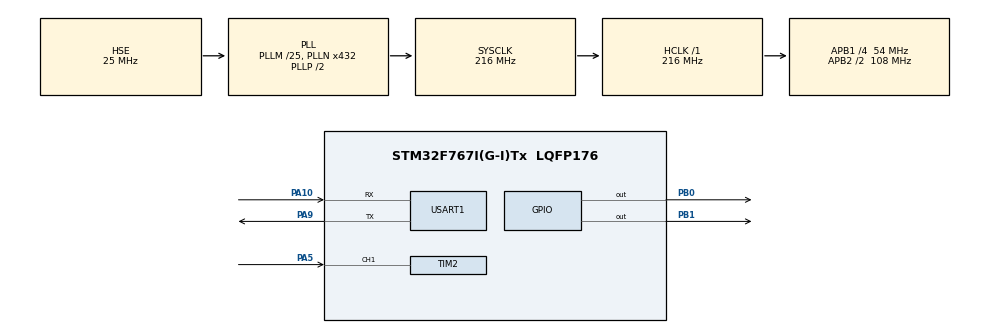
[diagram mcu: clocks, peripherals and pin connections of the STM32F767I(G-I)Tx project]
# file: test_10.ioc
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CORTEX_M7.default_mode_Activation=1
Mcu.Family=STM32F7
Mcu.Name=STM32F767I(G-I)Tx
Mcu.Package=LQFP176
NVIC.PriorityGroup=NVIC_PRIORITYGROUP_2
NVIC.USART1_IRQn=true\:3\:3\:true\:false\:true\:true\:true\:true
PA10.Mode=Asynchronous
PA10.Signal=USART1_RX
PA5.GPIO_ModeDefaultPP=GPIO_MODE_AF_PP
PA5.GPIO_PuPd=GPIO_NOPULL
PA5.GPIO_Speed=GPIO_SPEED_FREQ_HIGH
PA5.Signal=S_TIM2_CH1_ETR
PA9.Mode=Asynchronous
PA9.Signal=USART1_TX
PB0.GPIO_ModeDefaultOutputPP=GPIO_MODE_OUTPUT_PP
PB0.GPIO_PuPd=GPIO_PULLUP
PB0.GPIO_Speed=GPIO_SPEED_FREQ_HIGH
PB0.PinState=GPIO_PIN_SET
PB0.Signal=GPIO_Output
PB1.GPIO_ModeDefaultOutputPP=GPIO_MODE_OUTPUT_PP
PB1.GPIO_PuPd=GPIO_PULLUP
PB1.GPIO_Speed=GPIO_SPEED_FREQ_HIGH
PB1.PinState=GPIO_PIN_SET
PB1.Signal=GPIO_Output
PH0/OSC_IN.Mode=HSE-External-Oscillator
PH0/OSC_IN.Signal=RCC_OSC_IN
PH1/OSC_OUT.Mode=HSE-External-Oscillator
PH1/OSC_OUT.Signal=RCC_OSC_OUT
ProjectManager.HeapSize=0x200
ProjectManager.StackSize=0x400
ProjectManager.TargetToolchain=MDK-ARM V5.32
RCC.AHBFreq_Value=216000000
RCC.APB1CLKDivider=RCC_HCLK_DIV4
RCC.APB1Freq_Value=54000000
RCC.APB1TimFreq_Value=108000000
RCC.APB2CLKDivider=RCC_HCLK_DIV2
RCC.APB2Freq_Value=108000000
RCC.APB2TimFreq_Value=216000000
RCC.CortexFreq_Value=216000000
RCC.HCLKFreq_Value=216000000
RCC.HSE_VALUE=25000000
RCC.HSI_VALUE=16000000
RCC.LSE_VALUE=32768
RCC.PLLM=25
RCC.PLLN=432
RCC.PLLSourceVirtual=RCC_PLLSOURCE_HSE
RCC.SYSCLKFreq_VALUE=216000000
RCC.SYSCLKSource=RCC_SYSCLKSOURCE_PLLCLK
RCC.USBFreq_Value=216000000
RCC.VCOOutputFreq_Value=432000000
SH.S_TIM2_CH1_ETR.0=TIM2_CH1,Input_Capture1_from_TI1
TIM2.Channel-Input_Capture1_from_TI1=TIM_CHANNEL_1
TIM2.Period=0xffffffff
TIM2.Prescaler=7
USART1.VirtualMode-Asynchronous=VM_ASYNC
board=custom

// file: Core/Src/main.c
/* USER CODE BEGIN Header */
/**
  ******************************************************************************
  * @file           : main.c
  * @brief          : Main program body
  ******************************************************************************
  * @attention
  *
  * Copyright (c) 2022 STMicroelectronics.
  * All rights reserved.
  *
  * This software is licensed under terms that can be found in the LICENSE file
  * in the root directory of this software component.
  * If no LICENSE file comes with this software, it is provided AS-IS.
  *
  ******************************************************************************
  */
/* USER CODE END Header */
#include "main.h"
#include "tim.h"
#include "usart.h"
#include "gpio.h"

/* USER CODE BEGIN PD */
//LED端口定义
#define LED0_Toggle (HAL_GPIO_TogglePin(GPIOB, GPIO_PIN_1))
#define LED1_Toggle (HAL_GPIO_TogglePin(GPIOB, GPIO_PIN_0))
/* USER CODE END PD */

void SystemClock_Config(void);
static void MPU_Config(void);

int main(void)
{
  /* USER CODE BEGIN 1 */
  u8 t=0;
  /* USER CODE END 1 */

  /* MPU Configuration--------------------------------------------------------*/
  MPU_Config();

  /* MCU Configuration--------------------------------------------------------*/

  /* Reset of all peripherals, Initializes the Flash interface and the Systick. */
  HAL_Init();

  /* Configure the system clock */
  SystemClock_Config();

  /* Initialize all configured peripherals */
  MX_GPIO_Init();
  MX_TIM2_Init();
  MX_USART1_UART_Init();
  /* USER CODE BEGIN 2 */
  TPAD_Init();	//初始化触摸按键,以108/8=13.5Mhz频率计数
  /* USER CODE END 2 */

  /* Infinite loop */
  /* USER CODE BEGIN WHILE */
  while (1)
  {
	  if(TPAD_Scan(0))            //成功捕获到了一次上升沿(此函数执行时间至少15ms)
		{
			LED1_Toggle;            //LED1取反
		}
		t++;
		if(t==15)
		{
			t=0;
			LED0_Toggle;            //LED1翻转
		}
		HAL_Delay(10);
    /* USER CODE END WHILE */

  }
}

void SystemClock_Config(void)
{
  RCC_OscInitTypeDef RCC_OscInitStruct = {0};
  RCC_ClkInitTypeDef RCC_ClkInitStruct = {0};

  /** Configure the main internal regulator output voltage
  */
  __HAL_RCC_PWR_CLK_ENABLE();
  __HAL_PWR_VOLTAGESCALING_CONFIG(PWR_REGULATOR_VOLTAGE_SCALE1);

  /** Initializes the RCC Oscillators according to the specified parameters
  * in the RCC_OscInitTypeDef structure.
  */
  RCC_OscInitStruct.OscillatorType = RCC_OSCILLATORTYPE_HSE;
  RCC_OscInitStruct.HSEState = RCC_HSE_ON;
  RCC_OscInitStruct.PLL.PLLState = RCC_PLL_ON;
  RCC_OscInitStruct.PLL.PLLSource = RCC_PLLSOURCE_HSE;
  RCC_OscInitStruct.PLL.PLLM = 25;
  RCC_OscInitStruct.PLL.PLLN = 432;
  RCC_OscInitStruct.PLL.PLLP = RCC_PLLP_DIV2;
  RCC_OscInitStruct.PLL.PLLQ = 2;
  RCC_OscInitStruct.PLL.PLLR = 2;
  if (HAL_RCC_OscConfig(&RCC_OscInitStruct) != HAL_OK)
  {
    Error_Handler();
  }

  /** Activate the Over-Drive mode
  */
  if (HAL_PWREx_EnableOverDrive() != HAL_OK)
  {
    Error_Handler();
  }

  /** Initializes the CPU, AHB and APB buses clocks
  */
  RCC_ClkInitStruct.ClockType = RCC_CLOCKTYPE_HCLK|RCC_CLOCKTYPE_SYSCLK
                              |RCC_CLOCKTYPE_PCLK1|RCC_CLOCKTYPE_PCLK2;
  RCC_ClkInitStruct.SYSCLKSource = RCC_SYSCLKSOURCE_PLLCLK;
  RCC_ClkInitStruct.AHBCLKDivider = RCC_SYSCLK_DIV1;
  RCC_ClkInitStruct.APB1CLKDivider = RCC_HCLK_DIV4;
  RCC_ClkInitStruct.APB2CLKDivider = RCC_HCLK_DIV2;

  if (HAL_RCC_ClockConfig(&RCC_ClkInitStruct, FLASH_LATENCY_7) != HAL_OK)
  {
    Error_Handler();
  }
}

/* MPU Configuration */

void MPU_Config(void)
{
  MPU_Region_InitTypeDef MPU_InitStruct = {0};

  /* Disables the MPU */
  HAL_MPU_Disable();

  /** Initializes and configures the Region and the memory to be protected
  */
  MPU_InitStruct.Enable = MPU_REGION_ENABLE;
  MPU_InitStruct.Number = MPU_REGION_NUMBER0;
  MPU_InitStruct.BaseAddress = 0x0;
  MPU_InitStruct.Size = MPU_REGION_SIZE_4GB;
  MPU_InitStruct.SubRegionDisable = 0x87;
  MPU_InitStruct.TypeExtField = MPU_TEX_LEVEL0;
  MPU_InitStruct.AccessPermission = MPU_REGION_NO_ACCESS;
  MPU_InitStruct.DisableExec = MPU_INSTRUCTION_ACCESS_DISABLE;
  MPU_InitStruct.IsShareable = MPU_ACCESS_SHAREABLE;
  MPU_InitStruct.IsCacheable = MPU_ACCESS_NOT_CACHEABLE;
  MPU_InitStruct.IsBufferable = MPU_ACCESS_NOT_BUFFERABLE;

  HAL_MPU_ConfigRegion(&MPU_InitStruct);
  /* Enables the MPU */
  HAL_MPU_Enable(MPU_PRIVILEGED_DEFAULT);

}

void Error_Handler(void)
{
  __disable_irq();
  while (1)
  {
  }
}
